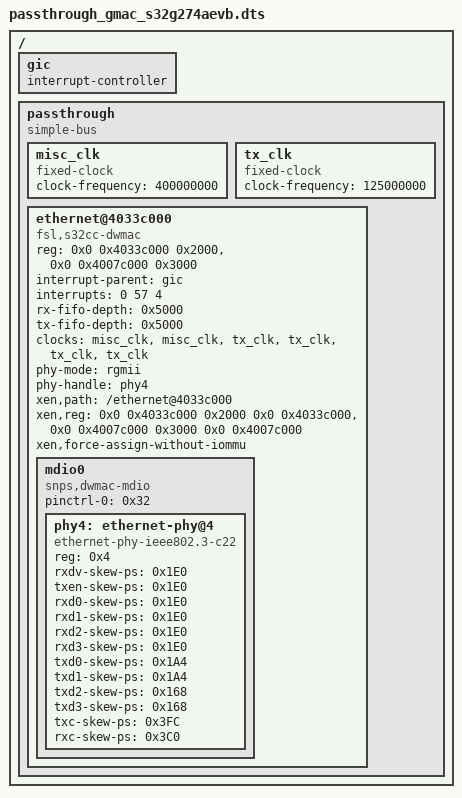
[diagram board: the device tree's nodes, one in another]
/*
 * Copyright 2021 NXP
 *
 * This program is free software; you can redistribute it and/or
 * modify it under the terms and conditions of the GNU General Public
 * License, version 2, as published by the Free Software Foundation.
 *
 * This program is distributed in the hope that it will be useful,
 * but WITHOUT ANY WARRANTY; without even the implied warranty of
 * MERCHANTABILITY or FITNESS FOR A PARTICULAR PURPOSE. See the GNU
 * General Public License for more details.
 *
 * You should have received a copy of the GNU General Public
 * License along with this program; If not, see <http://www.gnu.org/licenses/>.
 */

/dts-v1/;

/ {
    #address-cells = <2>;
    #size-cells = <1>;

    gic: gic {
        #interrupt-cells = <3>;
        interrupt-controller;
    };

    passthrough {
        compatible = "simple-bus";
        ranges;
        #address-cells = <2>;
        #size-cells = <1>;

        /* CLK_XBAR */
        misc_clk: misc_clk {
            #clock-cells = <0>;
            clock-frequency = <400000000>;
            compatible = "fixed-clock";
        };

        /* CLK_GMAC_0_TX */
        tx_clk: tx_clk {
            #clock-cells = <0>;
            clock-frequency = <125000000>;
            compatible = "fixed-clock";
        };

        ethernet@4033c000 {
            compatible = "fsl,s32cc-dwmac";
            status = "okay";
            reg = <0x0 0x4033c000 0x2000>,
		<0x0 0x4007c000 0x3000>;
            interrupt-parent = <&gic>;
            interrupts = <0 57 4>;
            interrupt-names = "macirq";
            rx-fifo-depth = <0x5000>;
            tx-fifo-depth = <0x5000>;
            clock-names = "stmmaceth", "pclk",
			"tx_sgmii", "tx_rgmii",
			"tx_rmii", "tx_mii";
            clocks = <&misc_clk &misc_clk &tx_clk &tx_clk &tx_clk &tx_clk>;
            phy-mode = "rgmii";
            phy-handle = <&phy4>;
            xen,path = "/ethernet@4033c000";
            xen,reg = <0x0 0x4033c000 0x2000 0x0 0x4033c000>,
                    <0x0 0x4007c000 0x3000 0x0 0x4007c000>;
            xen,force-assign-without-iommu;
            mdio0 {
                compatible = "snps,dwmac-mdio";
                #address-cells = <1>;
                #size-cells = <0>;
                pinctrl-names = "default";
                pinctrl-0 = <0x32>;
                phy4: ethernet-phy@4 {
                    compatible = "ethernet-phy-ieee802.3-c22";
                    #address-cells = <0x1>;
                    #size-cells = <0x0>;
                    reg = <0x4>;
                    rxdv-skew-ps = <0x1E0>;
                    txen-skew-ps = <0x1E0>;
                    rxd0-skew-ps = <0x1E0>;
                    rxd1-skew-ps = <0x1E0>;
                    rxd2-skew-ps = <0x1E0>;
                    rxd3-skew-ps = <0x1E0>;
                    txd0-skew-ps = <0x1A4>;
                    txd1-skew-ps = <0x1A4>;
                    txd2-skew-ps = <0x168>;
                    txd3-skew-ps = <0x168>;
                    txc-skew-ps = <0x3FC>;
                    rxc-skew-ps = <0x3C0>;
                    phandle = <0x30>;
                };
            };
        };
    };
};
